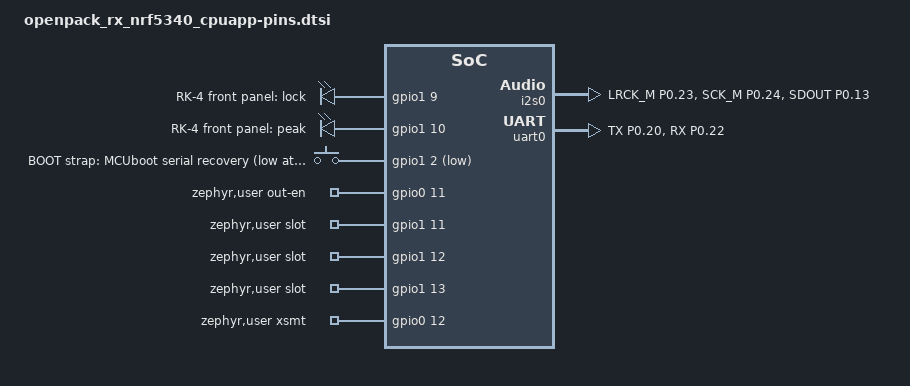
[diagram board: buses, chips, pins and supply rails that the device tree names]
/* GENERATED by fw/boards/openpack/gen_pins.py from hw/rx/out/rx.net (hw/rx/rx.py, ADR-0014). Do not edit:
 * change the schematic, rerun hw/rx/rx.py, then gen_pins.py.
 * openpack_rx/nrf5340/cpuapp. tests/test_fw_board_pins.py checks it against the netlist. */

&pinctrl {
	/* i2s0: I2S_LRCK_M=I2S_LRCK@C4, I2S_SCK_M=I2S_BCK@C3, I2S_SDOUT=I2S_SDOUT@B6 */
	i2s0_default: i2s0_default {
		group1 {
			psels = <NRF_PSEL(I2S_LRCK_M, 0, 23)>,
				<NRF_PSEL(I2S_SCK_M, 0, 24)>,
				<NRF_PSEL(I2S_SDOUT, 0, 13)>;
		};
	};
	i2s0_sleep: i2s0_sleep {
		group1 {
			psels = <NRF_PSEL(I2S_LRCK_M, 0, 23)>,
				<NRF_PSEL(I2S_SCK_M, 0, 24)>,
				<NRF_PSEL(I2S_SDOUT, 0, 13)>;
			low-power-enable;
		};
	};
	/* uart0: UART_RX=UART_RX@D5, UART_TX=UART_TX@C5 */
	uart0_default: uart0_default {
		group1 {
			psels = <NRF_PSEL(UART_TX, 0, 20)>;
		};
		group2 {
			psels = <NRF_PSEL(UART_RX, 0, 22)>;
			bias-pull-up;
		};
	};
	uart0_sleep: uart0_sleep {
		group1 {
			psels = <NRF_PSEL(UART_TX, 0, 20)>;
			low-power-enable;
		};
		group2 {
			psels = <NRF_PSEL(UART_RX, 0, 22)>;
			low-power-enable;
			bias-pull-up;
		};
	};
};

&i2s0 {
	pinctrl-0 = <&i2s0_default>;
	pinctrl-1 = <&i2s0_sleep>;
	pinctrl-names = "default", "sleep";
};

&uart0 {
	pinctrl-0 = <&uart0_default>;
	pinctrl-1 = <&uart0_sleep>;
	pinctrl-names = "default", "sleep";
};

/ {
	leds {
		compatible = "gpio-leds";
		led_lock: led_lock {
			gpios = <&gpio1 9 GPIO_ACTIVE_HIGH>; /* LED_LOCK@Z0 */
			label = "RK-4 front panel: lock";
		};
		led_peak: led_peak {
			gpios = <&gpio1 10 GPIO_ACTIVE_HIGH>; /* LED_PEAK@Z1 */
			label = "RK-4 front panel: peak";
		};
	};

	buttons {
		compatible = "gpio-keys";
		boot_btn: boot_btn {
			gpios = <&gpio1 2 GPIO_ACTIVE_LOW>; /* BOOT@1, external pull-up */
			label = "BOOT strap: MCUboot serial recovery (low at reset)";
			zephyr,code = <INPUT_KEY_0>;
		};
	};

	aliases {
		mcuboot-button0 = &boot_btn;
	};

	zephyr,user {
		out-en-gpios = <&gpio0 11 GPIO_ACTIVE_HIGH>; /* OUT_EN@12 */
		slot-gpios = <&gpio1 11 GPIO_ACTIVE_HIGH>, <&gpio1 12 GPIO_ACTIVE_HIGH>, <&gpio1 13 GPIO_ACTIVE_HIGH>; /* SLOT0@Z2, SLOT1@Z3, SLOT2@Z4 */
		xsmt-gpios = <&gpio0 12 GPIO_ACTIVE_HIGH>; /* XSMT_EN@B5 */
	};

	/* net-core pins, handed over at net-core boot (SOC_NRF_GPIO_FORWARDER_FOR_NRF5340) */
	gpio_fwd: nrf-gpio-forwarder {
		compatible = "nordic,nrf-gpio-forwarder";
		status = "okay";

		net {
			gpios = <&gpio1 1 0>;
			/* ANT_SEL@D6 */
		};
	};
};
